VERSION ""

NS_ :

BS_:

BU_:

BO_ 1330 update_data_message: 8 Vector__XXX
 SG_ data_block_index_low : 0|8@1+ (1,0) [0|0] "" Vector__XXX
 SG_ update_data : 8|56@1+ (1,0) [0|0] "" Vector__XXX

BO_ 1331 update_info_message: 6 Vector__XXX
 SG_ message_type M : 0|8@1+ (1,0) [0|0] "" Vector__XXX
 SG_ update_length m0 : 8|32@1+ (1,0) [0|0] "" Vector__XXX
 SG_ update_md5 m1 : 16|32@1+ (1,0) [0|0] "" Vector__XXX
 SG_ update_md5_idx m1 : 8|8@1+ (1,0) [0|0] "" Vector__XXX

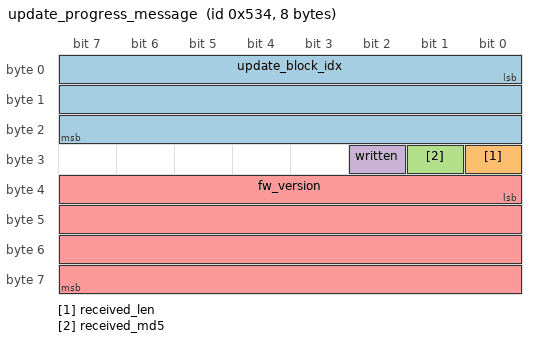
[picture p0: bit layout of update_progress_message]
BO_ 1332 update_progress_message: 8 Vector__XXX
 SG_ update_block_idx : 0|24@1+ (1,0) [0|0] "" Vector__XXX
 SG_ received_len : 24|1@1+ (1,0) [0|0] "" Vector__XXX
 SG_ received_md5 : 25|1@1+ (1,0) [0|0] "" Vector__XXX
 SG_ written : 26|1@1+ (1,0) [0|0] "" Vector__XXX
 SG_ fw_version : 32|32@1+ (1,0) [0|0] "" Vector__XXX

VAL_ 1331 message_type 0 "UpdateStart" 1 "Md5";
